# apb_uart: IP-XACT component
VLNV pulp-platform.org:peripheral:apb_uart:1.0

## Bus interfaces (logical=physical port)
apb_slave: slave amba.com:AMBA3:APB:r1p0_4, memory map UART
  PADDR[4:2]=PADDR[2:0], PSELx[0:0]=PSEL[0:0], PENABLE[0:0]=PENABLE[0:0], PWRITE[0:0]=PWRITE[0:0], PRDATA=PRDATA, PWDATA=PWDATA, PREADY[0:0]=PREADY[0:0], PSLVERR[0:0]=PSLVERR[0:0]
uart: slave pulp-platform.org:interface:uart:1.0
  dsr[0:0]=DSRN[0:0], cts[0:0]=CTSN[0:0], dtr[0:0]=DTRN[0:0], rts[0:0]=RTSN[0:0], rx=SIN, tx=SOUT
event: system pulp-platform.org:interface:irq:1.0
  event=INT

## Ports
in CLK
in RSTN
in PSEL
in PENABLE
in PWRITE
in PADDR[2:0]
in PWDATA[31:0]
out PRDATA[31:0]
out PREADY
out PSLVERR
out INT
out OUT1N
out OUT2N
out RTSN
out DTRN
in CTSN
in DSRN
in DCDN
in RIN
in SIN
out SOUT — Transmitter output

## Address spaces and blocks
UART.uart_registers: base 'h0, range 8, width 8

## Registers
Registers are 8-bit, access not given, no defined reset value unless marked. A register's access mark holds for its fields unless they carry their own. Offsets are from the block's base; lines under a group give offsets from that group; [hi:lo] are bit positions; {n}, {i} and the like mark numbered series; 'fields as' and 'values as' point back to an identical list; <NAME> marks a mode.

## UART.uart_registers
Base 0x00000000
0x00 THR_RBR_DLL
  [7:0] Variant
0x01 IER_DLH
  [7:0] Variant
0x02 IIR_FCR
  [7:0] Variant
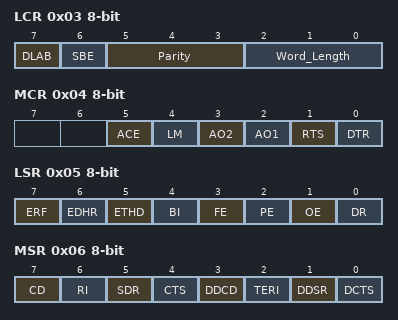
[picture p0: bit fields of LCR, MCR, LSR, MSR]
0x03 LCR
  [7] DLAB, [6] SBE, [5:3] Parity, [2:0] Word_Length
0x04 MCR
  [5] ACE, [4] LM, [3] AO2, [2] AO1, [1] RTS, [0] DTR
0x05 LSR
  [7] ERF, [6] EDHR, [5] ETHD, [4] BI, [3] FE, [2] PE, [1] OE, [0] DR
0x06 MSR
  [7] CD, [6] RI, [5] SDR, [4] CTS, [3] DDCD, [2] TERI, [1] DDSR, [0] DCTS
0x07 SR

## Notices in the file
LGPL2
